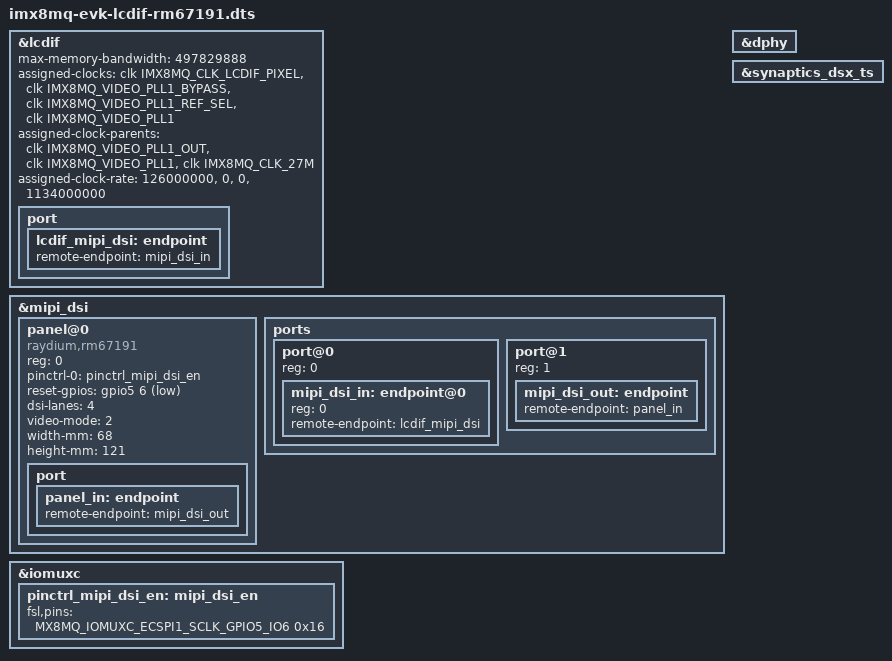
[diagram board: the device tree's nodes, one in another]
/*
 * Copyright 2018 NXP
 *
 * This program is free software; you can redistribute it and/or
 * modify it under the terms of the GNU General Public License
 * as published by the Free Software Foundation; either version 2
 * of the License, or (at your option) any later version.
 *
 * This program is distributed in the hope that it will be useful,
 * but WITHOUT ANY WARRANTY; without even the implied warranty of
 * MERCHANTABILITY or FITNESS FOR A PARTICULAR PURPOSE.  See the
 * GNU General Public License for more details.
 */

#include "imx8mq-evk.dts"

&lcdif {
	status = "okay";
	max-memory-bandwidth = <497829888>; /* 1920x1080-32@60.02 */

	assigned-clocks = <&clk IMX8MQ_CLK_LCDIF_PIXEL>,
			  <&clk IMX8MQ_VIDEO_PLL1_BYPASS>,
			  <&clk IMX8MQ_VIDEO_PLL1_REF_SEL>,
			  <&clk IMX8MQ_VIDEO_PLL1>;
	assigned-clock-parents = <&clk IMX8MQ_VIDEO_PLL1_OUT>,
				 <&clk IMX8MQ_VIDEO_PLL1>,
				 <&clk IMX8MQ_CLK_27M>;
	assigned-clock-rate = <126000000>, <0>, <0>, <1134000000>;

	port {
		lcdif_mipi_dsi: endpoint {
			remote-endpoint = <&mipi_dsi_in>;
		};
	};
};

&mipi_dsi {
	status = "okay";
	#address-cells = <1>;
	#size-cells = <0>;

	panel@0 {
		compatible = "raydium,rm67191";
		reg = <0>;
		pinctrl-0 = <&pinctrl_mipi_dsi_en>;
		pinctrl-names = "default";
		reset-gpios = <&gpio5 6 GPIO_ACTIVE_LOW>;
		dsi-lanes = <4>;
		video-mode = <2>;
		width-mm = <68>;
		height-mm = <121>;
		port {
			panel_in: endpoint {
				remote-endpoint = <&mipi_dsi_out>;
			};
		};
	};

	ports {
		#address-cells = <1>;
		#size-cells = <0>;

		port@0 {
			#address-cells = <1>;
			#size-cells = <0>;
			reg = <0>;
			mipi_dsi_in: endpoint@0 {
				reg = <0>;
				remote-endpoint = <&lcdif_mipi_dsi>;
			};
		};

		port@1 {
			reg = <1>;
			mipi_dsi_out: endpoint {
				remote-endpoint = <&panel_in>;
			};
		};
	};
};

&dphy {
	status = "okay";
};

&iomuxc {
	pinctrl_mipi_dsi_en: mipi_dsi_en {
		fsl,pins = <
			MX8MQ_IOMUXC_ECSPI1_SCLK_GPIO5_IO6	0x16
		>;
	};
};

&synaptics_dsx_ts {
	status = "okay";
};
